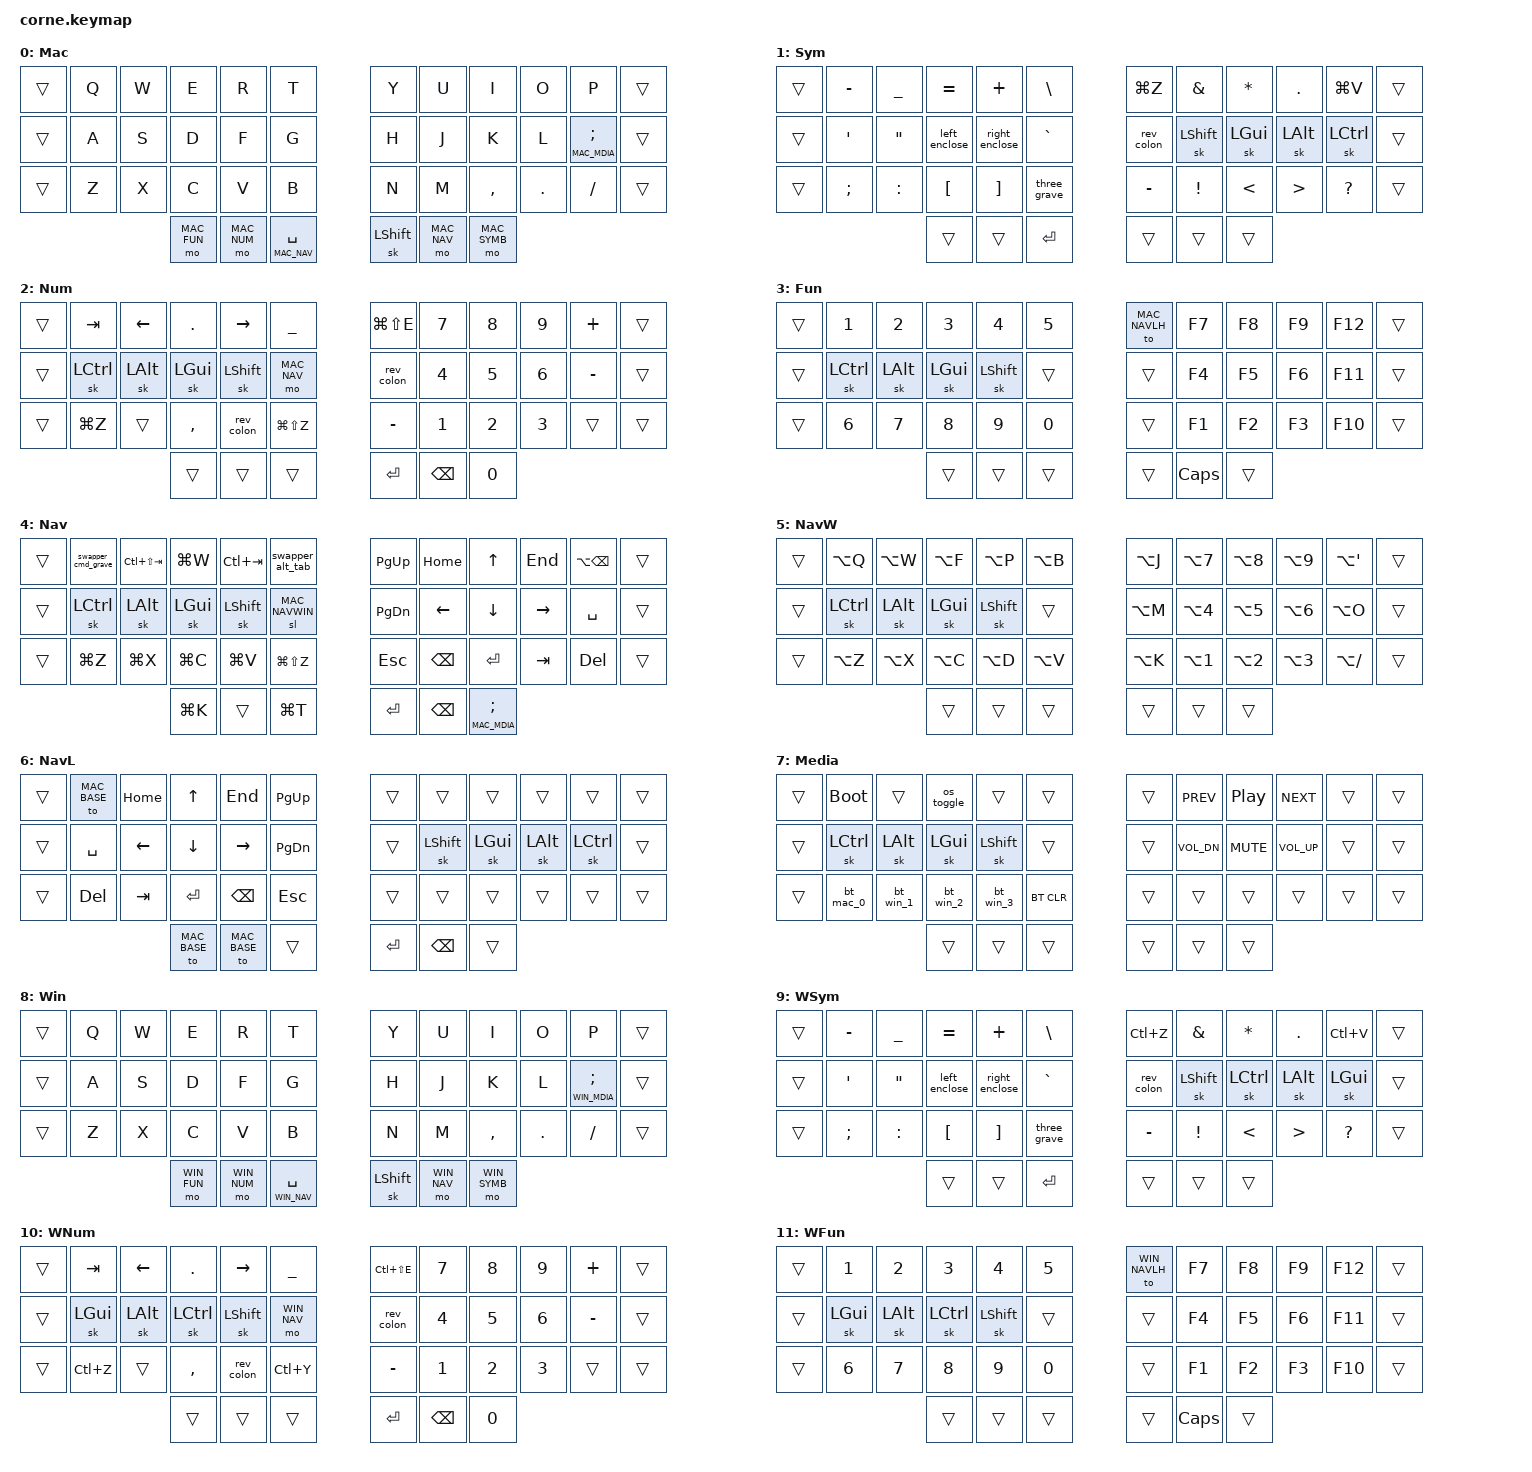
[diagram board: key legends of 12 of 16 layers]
/*
 * Copyright (c) 2020 The ZMK Contributors
 *
 * SPDX-License-Identifier: MIT
 */

#include <behaviors.dtsi>
#include <dt-bindings/zmk/keys.h>
#include <dt-bindings/zmk/bt.h>
#include <dt-bindings/zmk/outputs.h>

/* Layer definitions - Mac Mode (0-7) and Windows Mode (8-15) */
#define MAC_BASE    0
#define MAC_SYMB    1
#define MAC_NUM     2
#define MAC_FUN     3
#define MAC_NAV     4
#define MAC_NAVWIN  5
#define MAC_NAVLH   6
#define MAC_MDIA    7

#define WIN_BASE    8
#define WIN_SYMB    9
#define WIN_NUM     10
#define WIN_FUN     11
#define WIN_NAV     12
#define WIN_NAVWIN  13
#define WIN_NAVLH   14
#define WIN_MDIA    15

/* Common Key Aliases (OS-independent) */
#define BLANK              &trans

/* Letter Keys */
#define KEY_Q              &kp Q
#define KEY_W              &kp W
#define KEY_E              &kp E
#define KEY_R              &kp R
#define KEY_T              &kp T
#define KEY_Y              &kp Y
#define KEY_U              &kp U
#define KEY_I              &kp I
#define KEY_O              &kp O
#define KEY_P              &kp P
#define KEY_A              &kp A
#define KEY_S              &kp S
#define KEY_D              &kp D
#define KEY_F              &kp F
#define KEY_G              &kp G
#define KEY_H              &kp H
#define KEY_J              &kp J
#define KEY_K              &kp K
#define KEY_L              &kp L
#define KEY_Z              &kp Z
#define KEY_X              &kp X
#define KEY_C              &kp C
#define KEY_V              &kp V
#define KEY_B              &kp B
#define KEY_N              &kp N
#define KEY_M              &kp M
#define KEY_COMMA          &kp COMMA
#define KEY_DOT            &kp DOT
#define KEY_FSLH           &kp FSLH

/* Number Keys */
#define KEY_1              &kp N1
#define KEY_2              &kp N2
#define KEY_3              &kp N3
#define KEY_4              &kp N4
#define KEY_5              &kp N5
#define KEY_6              &kp N6
#define KEY_7              &kp N7
#define KEY_8              &kp N8
#define KEY_9              &kp N9
#define KEY_0              &kp N0

/* Symbol Keys */
#define SYM_MINUS          &kp MINUS
#define SYM_UNDER          &kp UNDER
#define SYM_EQUAL          &kp EQUAL
#define SYM_PLUS           &kp PLUS
#define SYM_BSLH           &kp BSLH
#define SYM_SQT            &kp SQT
#define SYM_DQT            &kp DQT
#define SYM_GRAVE          &kp GRAVE
#define SYM_SEMI           &kp SEMI
#define SYM_COLON          &kp COLON
#define SYM_LBKT           &kp LBKT
#define SYM_RBKT           &kp RBKT
#define SYM_AMPS           &kp AMPS
#define SYM_ASTRK          &kp ASTRK
#define SYM_EXCL           &kp EXCL
#define SYM_LT             &kp LT
#define SYM_GT             &kp GT
#define SYM_QMARK          &kp QMARK

/* Function Keys */
#define FUN_F1             &kp F1
#define FUN_F2             &kp F2
#define FUN_F3             &kp F3
#define FUN_F4             &kp F4
#define FUN_F5             &kp F5
#define FUN_F6             &kp F6
#define FUN_F7             &kp F7
#define FUN_F8             &kp F8
#define FUN_F9             &kp F9
#define FUN_F10            &kp F10
#define FUN_F11            &kp F11
#define FUN_F12            &kp F12

/* Navigation Keys */
#define NAV_UP             &kp UP
#define NAV_DOWN           &kp DOWN
#define NAV_LEFT           &kp LEFT
#define NAV_RIGHT          &kp RIGHT
#define NAV_HOME           &kp HOME
#define NAV_END            &kp END
#define NAV_PGUP           &kp PG_UP
#define NAV_PGDN           &kp PG_DN

/* Common Keys */
#define KEY_TAB            &kp TAB
#define KEY_RET            &kp RET
#define KEY_ESC            &kp ESC
#define KEY_BSPC           &kp BSPC
#define KEY_DEL            &kp DEL
#define KEY_SPACE          &kp SPACE
#define KEY_CAPS           &kp CAPSLOCK

/* Media Keys */
#define MED_PREV           &kp C_PREV
#define MED_NEXT           &kp C_NEXT
#define MED_PLAY           &kp C_PP
#define MED_VOL_UP         &kp C_VOL_UP
#define MED_VOL_DN         &kp C_VOL_DN
#define MED_MUTE           &kp C_MUTE

/* System Keys */
#define SYS_BOOT           &bootloader

/* Bluetooth Keys */
#define BT_MAC_0           &bt_mac_0
#define BT_WIN_1           &bt_win_1
#define BT_WIN_2           &bt_win_2
#define BT_WIN_3           &bt_win_3
#define BT_CLEAR           &bt BT_CLR

/* Alt Layer Keys */
#define ALT_Q              &kp LA(Q)
#define ALT_W              &kp LA(W)
#define ALT_F              &kp LA(F)
#define ALT_P              &kp LA(P)
#define ALT_B              &kp LA(B)
#define ALT_J              &kp LA(J)
#define ALT_M              &kp LA(M)
#define ALT_K              &kp LA(K)
#define ALT_Z              &kp LA(Z)
#define ALT_X              &kp LA(X)
#define ALT_C              &kp LA(C)
#define ALT_D              &kp LA(D)
#define ALT_V              &kp LA(V)
#define ALT_O              &kp LA(O)
#define ALT_SQT            &kp LA(SQT)
#define ALT_FSLH           &kp LA(FSLH)
#define ALT_N1             &kp LA(N1)
#define ALT_N2             &kp LA(N2)
#define ALT_N3             &kp LA(N3)
#define ALT_N4             &kp LA(N4)
#define ALT_N5             &kp LA(N5)
#define ALT_N6             &kp LA(N6)
#define ALT_N7             &kp LA(N7)
#define ALT_N8             &kp LA(N8)
#define ALT_N9             &kp LA(N9)

/* OS-Specific Modifier Keys - Mac Mode */
#define MAC_OS_SHFT        &sk LSHFT
#define MAC_OS_CTRL        &sk LCTRL
#define MAC_OS_ALT         &sk LALT
#define MAC_OS_GUI         &sk LGUI

/* OS-Specific Modifier Keys - Windows Mode (GUI and CTRL swapped) */
#define WIN_OS_SHFT        &sk LSHFT
#define WIN_OS_CTRL        &sk LGUI  // Windows "Ctrl" is GUI key
#define WIN_OS_ALT         &sk LALT
#define WIN_OS_GUI         &sk LCTRL  // Windows "GUI" is Ctrl key

/* OS-Specific Layer Access Keys */
#define MAC_FUN_KEY        &mo MAC_FUN
#define MAC_NUM_KEY        &mo MAC_NUM
#define MAC_NAV_KEY        &mo MAC_NAV
#define MAC_SYMB_KEY       &mo MAC_SYMB
#define MAC_NAVWIN_KEY     &sl MAC_NAVWIN
#define MAC_NAVLH_KEY      &to MAC_NAVLH
#define MAC_BASE_KEY       &to MAC_BASE
#define MAC_SEMI_MDIA      &lt MAC_MDIA SEMI

#define WIN_FUN_KEY        &mo WIN_FUN
#define WIN_NUM_KEY        &mo WIN_NUM
#define WIN_NAV_KEY        &mo WIN_NAV
#define WIN_SYMB_KEY       &mo WIN_SYMB
#define WIN_NAVWIN_KEY     &sl WIN_NAVWIN
#define WIN_NAVLH_KEY      &to WIN_NAVLH
#define WIN_BASE_KEY       &to WIN_BASE
#define WIN_SEMI_MDIA      &lt WIN_MDIA SEMI

/* OS-Specific Space Keys with Layer Tap */
#define MAC_SPACE          &lt_sp_mac MAC_NAV SPACE
#define WIN_SPACE          &lt_sp_win WIN_NAV SPACE

/* OS-Specific Shortcuts - Mac */
#define MAC_UNDO           &kp LG(Z)
#define MAC_CUT            &kp LG(X)
#define MAC_COPY           &kp LG(C)
#define MAC_PASTE          &kp LG(V)
#define MAC_REDO           &kp LG(LS(Z))
#define MAC_CLS_WIN        &kp LG(W)
#define MAC_NWTB           &kp LG(T)
#define MAC_MKLNK          &kp LG(K)
#define MAC_VSC_EVAL       &kp LG(LS(E))
#define MAC_DWRD           &kp LA(BSPC)

/* OS-Specific Shortcuts - Windows/Linux */
#define WIN_UNDO           &kp LC(Z)
#define WIN_CUT            &kp LC(X)
#define WIN_COPY           &kp LC(C)
#define WIN_PASTE          &kp LC(V)
#define WIN_REDO           &kp LC(Y)
#define WIN_CLS_WIN        &kp LC(W)
#define WIN_NWTB           &kp LC(T)
#define WIN_MKLNK          &kp LC(K)
#define WIN_VSC_EVAL       &kp LC(LS(E))
#define WIN_DWRD           &kp LC(BSPC)

/* Tab Navigation */
#define TAB_PREV           &kp LC(LS(TAB))
#define TAB_NEXT           &kp LC(TAB)

/* Custom Behaviors */
#define OS_TOGGLE          &os_toggle
#define REV_COLON          &rev_colon
#define LEFT_ENCLOSE       &left_enclose
#define RIGHT_ENCLOSE      &right_enclose
#define THREE_GRAVE        &three_grave
#define SW_APP             &swapper_alt_tab
#define SW_WIN             &swapper_cmd_grave

/* Custom behaviors */
/ {
    behaviors {
        // OS toggle: Switch between Mac (layers 0-7) and Windows (layers 8-15) mode
        os_toggle: os_toggle {
            compatible = "zmk,behavior-mod-morph";
            #binding-cells = <0>;
            bindings = <&to WIN_BASE>, <&to MAC_BASE>;
            mods = <(MOD_LSFT|MOD_RSFT)>;
        };

        // Swapper behavior for Alt+Tab functionality
        swapper_alt_tab: swapper_alt_tab {
            compatible = "zmk,behavior-tri-state";
            #binding-cells = <0>;
            bindings = <&kt LALT>, <&kp TAB>, <&kt LALT>;
            timeout-ms = <3000>;
        };

        // Swapper behavior for Cmd+` functionality  
        swapper_cmd_grave: swapper_cmd_grave {
            compatible = "zmk,behavior-tri-state";
            #binding-cells = <0>;
            bindings = <&kt LGUI>, <&kp GRAVE>, <&kt LGUI>;
            timeout-ms = <3000>;
        };

        // Reversed colon/semicolon (colon by default, semicolon with shift)
        rev_colon: reversed_colon {
            compatible = "zmk,behavior-mod-morph";
            #binding-cells = <0>;
            bindings = <&kp COLON>, <&kp SEMI>;
            mods = <(MOD_LSFT|MOD_RSFT)>;
        };

        // Left enclosure behavior (parenthesis by default, brace with shift)
        left_enclose: left_enclosure {
            compatible = "zmk,behavior-mod-morph";
            #binding-cells = <0>;
            bindings = <&kp LPAR>, <&kp LBRC>;
            mods = <(MOD_LSFT|MOD_RSFT)>;
        };

        // Right enclosure behavior (parenthesis by default, brace with shift)
        right_enclose: right_enclosure {
            compatible = "zmk,behavior-mod-morph";
            #binding-cells = <0>;
            bindings = <&kp RPAR>, <&kp RBRC>;
            mods = <(MOD_LSFT|MOD_RSFT)>;
        };

        // Three backticks macro
        three_grave: three_grave_macro {
            compatible = "zmk,behavior-macro";
            #binding-cells = <0>;
            bindings = <&macro_tap &kp GRAVE &kp GRAVE &kp GRAVE>;
        };

        // Custom mod-tap with longer tapping term for space - Mac version
        lt_sp_mac: layer_tap_space_mac {
            compatible = "zmk,behavior-hold-tap";
            #binding-cells = <2>;
            flavor = "balanced";
            tapping-term-ms = <200>;
            quick-tap-ms = <150>;
            bindings = <&mo>, <&kp>;
        };

        // Custom mod-tap with longer tapping term for space - Windows version
        lt_sp_win: layer_tap_space_win {
            compatible = "zmk,behavior-hold-tap";
            #binding-cells = <2>;
            flavor = "balanced";
            tapping-term-ms = <200>;
            quick-tap-ms = <150>;
            bindings = <&mo>, <&kp>;
        };

        // Smart Bluetooth selection macros that auto-switch OS modes
        bt_mac_0: bt_mac_profile_0 {
            compatible = "zmk,behavior-macro";
            #binding-cells = <0>;
            bindings = <&bt BT_SEL 0>, <&to MAC_BASE>;
        };

        bt_win_1: bt_win_profile_1 {
            compatible = "zmk,behavior-macro";
            #binding-cells = <0>;
            bindings = <&bt BT_SEL 1>, <&to WIN_BASE>;
        };

        bt_win_2: bt_win_profile_2 {
            compatible = "zmk,behavior-macro";
            #binding-cells = <0>;
            bindings = <&bt BT_SEL 2>, <&to WIN_BASE>;
        };

        bt_win_3: bt_win_profile_3 {
            compatible = "zmk,behavior-macro";
            #binding-cells = <0>;
            bindings = <&bt BT_SEL 3>, <&to WIN_BASE>;
        };
    };

    combos {
        compatible = "zmk,combos";

        // Mac mode combos
        combo_nei_ctrl_mac {
            timeout-ms = <50>;
            key-positions = <16 17 18>; // N E I positions (3x6 layout with offset)
            bindings = <&sk LCTRL>;
            layers = <MAC_BASE MAC_SYMB MAC_NUM MAC_FUN MAC_NAV MAC_NAVWIN MAC_NAVLH>;
        };

        combo_commadot_semicolon_mac {
            timeout-ms = <50>;
            key-positions = <33 34>; // Comma and Dot positions (3x6 layout with offset)
            bindings = <&kp SEMI>;
            layers = <MAC_BASE MAC_SYMB MAC_NUM MAC_FUN MAC_NAV MAC_NAVWIN MAC_NAVLH>;
        };

        combo_hcomma_hyphen_mac {
            timeout-ms = <50>;
            key-positions = <16 33>; // H and Comma positions (3x6 layout with offset)
            bindings = <&kp MINUS>;
            layers = <MAC_BASE MAC_SYMB MAC_NUM MAC_FUN MAC_NAV MAC_NAVWIN MAC_NAVLH>;
        };

        combo_zd_tab_mac {
            timeout-ms = <50>;
            key-positions = <25 15>; // Z and D positions (3x6 layout with offset)
            bindings = <&kp TAB>;
            layers = <MAC_BASE MAC_SYMB MAC_NUM MAC_FUN MAC_NAV MAC_NAVWIN MAC_NAVLH>;
        };

        combo_xd_ctrl_mac {
            timeout-ms = <50>;
            key-positions = <26 15>; // X and D positions (3x6 layout with offset)
            bindings = <&sk LCTRL>;
            layers = <MAC_BASE MAC_SYMB MAC_NUM MAC_FUN MAC_NAV MAC_NAVWIN MAC_NAVLH>;
        };

        combo_dh_ctrl_mac {
            timeout-ms = <50>;
            key-positions = <15 18>; // D and H positions (3x6 layout with offset)
            bindings = <&sk LCTRL>;
            layers = <MAC_BASE MAC_SYMB MAC_NUM MAC_FUN MAC_NAV MAC_NAVWIN MAC_NAVLH>;
        };

        combo_prev_next_select_all_mac {
            timeout-ms = <50>;
            key-positions = <4 5>; // R and T positions (3x6 layout with offset)
            bindings = <&kp LG(A)>;
            layers = <MAC_BASE MAC_SYMB MAC_NUM MAC_FUN MAC_NAV MAC_NAVWIN MAC_NAVLH>;
        };

        // Windows mode combos (identical positions, different bindings)
        combo_nei_ctrl_win {
            timeout-ms = <50>;
            key-positions = <16 17 18>; // N E I positions (3x6 layout with offset)
            bindings = <&sk LGUI>;
            layers = <WIN_BASE WIN_SYMB WIN_NUM WIN_FUN WIN_NAV WIN_NAVWIN WIN_NAVLH>;
        };

        combo_commadot_semicolon_win {
            timeout-ms = <50>;
            key-positions = <33 34>; // Comma and Dot positions (3x6 layout with offset)
            bindings = <&kp SEMI>;
            layers = <WIN_BASE WIN_SYMB WIN_NUM WIN_FUN WIN_NAV WIN_NAVWIN WIN_NAVLH>;
        };

        combo_hcomma_hyphen_win {
            timeout-ms = <50>;
            key-positions = <16 33>; // H and Comma positions (3x6 layout with offset)
            bindings = <&kp MINUS>;
            layers = <WIN_BASE WIN_SYMB WIN_NUM WIN_FUN WIN_NAV WIN_NAVWIN WIN_NAVLH>;
        };

        combo_zd_tab_win {
            timeout-ms = <50>;
            key-positions = <25 15>; // Z and D positions (3x6 layout with offset)
            bindings = <&kp TAB>;
            layers = <WIN_BASE WIN_SYMB WIN_NUM WIN_FUN WIN_NAV WIN_NAVWIN WIN_NAVLH>;
        };

        combo_xd_ctrl_win {
            timeout-ms = <50>;
            key-positions = <26 15>; // X and D positions (3x6 layout with offset)
            bindings = <&sk LGUI>;
            layers = <WIN_BASE WIN_SYMB WIN_NUM WIN_FUN WIN_NAV WIN_NAVWIN WIN_NAVLH>;
        };

        combo_dh_ctrl_win {
            timeout-ms = <50>;
            key-positions = <15 18>; // D and H positions (3x6 layout with offset)
            bindings = <&sk LGUI>;
            layers = <WIN_BASE WIN_SYMB WIN_NUM WIN_FUN WIN_NAV WIN_NAVWIN WIN_NAVLH>;
        };

        combo_prev_next_select_all_win {
            timeout-ms = <50>;
            key-positions = <4 5>; // R and T positions (3x6 layout with offset)
            bindings = <&kp LC(A)>;
            layers = <WIN_BASE WIN_SYMB WIN_NUM WIN_FUN WIN_NAV WIN_NAVWIN WIN_NAVLH>;
        };
    };

        keymap {
                compatible = "zmk,keymap";

        // MAC MODE LAYERS (0-7)
        mac_base_layer {
            display-name = "Mac";
            bindings = <
            // ╭─────────┬─────────┬─────────┬─────────┬─────────╮   ╭─────────┬─────────┬─────────┬─────────┬─────────╮
        BLANK     KEY_Q     KEY_W     KEY_E     KEY_R     KEY_T         KEY_Y     KEY_U     KEY_I     KEY_O     KEY_P        BLANK
            // ├─────────┼─────────┼─────────┼─────────┼─────────┤   ├─────────┼─────────┼─────────┼─────────┼─────────┤
        BLANK     KEY_A     KEY_S     KEY_D     KEY_F     KEY_G         KEY_H     KEY_J     KEY_K     KEY_L   MAC_SEMI_MDIA  BLANK
            // ├─────────┼─────────┼─────────┼─────────┼─────────┤   ├─────────┼─────────┼─────────┼─────────┼─────────┤
        BLANK     KEY_Z     KEY_X     KEY_C     KEY_V     KEY_B         KEY_N     KEY_M   KEY_COMMA  KEY_DOT   KEY_FSLH      BLANK
            // ╰─────────┴─────────┼─────────┼─────────┼─────────┤   ├─────────┼─────────┼─────────┴─────────┴─────────╯
                                   MAC_FUN_KEY MAC_NUM_KEY MAC_SPACE MAC_OS_SHFT MAC_NAV_KEY MAC_SYMB_KEY
            //                     ╰─────────┴─────────┴─────────╯   ╰─────────┴─────────┴─────────╯
            >;
        };

        mac_symb_layer {
            display-name = "Sym";
            bindings = <
            // ╭─────────┬─────────┬─────────┬─────────┬─────────╮   ╭─────────┬─────────┬─────────┬─────────┬─────────╮
        BLANK   SYM_MINUS SYM_UNDER SYM_EQUAL  SYM_PLUS  SYM_BSLH    MAC_UNDO  SYM_AMPS  SYM_ASTRK  KEY_DOT  MAC_PASTE   BLANK
            // ├─────────┼─────────┼─────────┼─────────┼─────────┤   ├─────────┼─────────┼─────────┼─────────┼─────────┤
        BLANK    SYM_SQT   SYM_DQT  LEFT_ENCLOSE RIGHT_ENCLOSE SYM_GRAVE REV_COLON MAC_OS_SHFT MAC_OS_GUI MAC_OS_ALT MAC_OS_CTRL BLANK
            // ├─────────┼─────────┼─────────┼─────────┼─────────┤   ├─────────┼─────────┼─────────┼─────────┼─────────┤
        BLANK   SYM_SEMI  SYM_COLON  SYM_LBKT   SYM_RBKT THREE_GRAVE SYM_MINUS  SYM_EXCL   SYM_LT    SYM_GT  SYM_QMARK   BLANK
            // ╰─────────┴─────────┼─────────┼─────────┼─────────┤   ├─────────┼─────────┼─────────┴─────────┴─────────╯
                                     BLANK       BLANK      KEY_RET     BLANK       BLANK       BLANK
            //                     ╰─────────┴─────────┴─────────╯   ╰─────────┴─────────┴─────────╯
            >;
        };

        mac_num_layer {
            display-name = "Num";
            bindings = <
            // ╭─────────┬─────────┬─────────┬─────────┬─────────╮   ╭─────────┬─────────┬─────────┬─────────┬─────────╮
        BLANK    KEY_TAB   NAV_LEFT   KEY_DOT  NAV_RIGHT SYM_UNDER MAC_VSC_EVAL  KEY_7     KEY_8     KEY_9    SYM_PLUS    BLANK
            // ├─────────┼─────────┼─────────┼─────────┼─────────┤   ├─────────┼─────────┼─────────┼─────────┼─────────┤
        BLANK  MAC_OS_CTRL MAC_OS_ALT MAC_OS_GUI MAC_OS_SHFT MAC_NAV_KEY REV_COLON  KEY_4     KEY_5     KEY_6   SYM_MINUS   BLANK
            // ├─────────┼─────────┼─────────┼─────────┼─────────┤   ├─────────┼─────────┼─────────┼─────────┼─────────┤
        BLANK   MAC_UNDO    BLANK    KEY_COMMA REV_COLON MAC_REDO  SYM_MINUS   KEY_1     KEY_2     KEY_3      BLANK      BLANK
            // ╰─────────┴─────────┼─────────┼─────────┼─────────┤   ├─────────┼─────────┼─────────┴─────────┴─────────╯
                                     BLANK       BLANK      BLANK     KEY_RET   KEY_BSPC    KEY_0
            //                     ╰─────────┴─────────┴─────────╯   ╰─────────┴─────────┴─────────╯
            >;
        };

        mac_fun_layer {
            display-name = "Fun";
            bindings = <
            // ╭─────────┬─────────┬─────────┬─────────┬─────────╮   ╭─────────┬─────────┬─────────┬─────────┬─────────╮
        BLANK     KEY_1     KEY_2     KEY_3     KEY_4     KEY_5   MAC_NAVLH_KEY FUN_F7    FUN_F8    FUN_F9   FUN_F12     BLANK
            // ├─────────┼─────────┼─────────┼─────────┼─────────┤   ├─────────┼─────────┼─────────┼─────────┼─────────┤
        BLANK  MAC_OS_CTRL MAC_OS_ALT MAC_OS_GUI MAC_OS_SHFT  BLANK      BLANK     FUN_F4    FUN_F5    FUN_F6   FUN_F11     BLANK
            // ├─────────┼─────────┼─────────┼─────────┼─────────┤   ├─────────┼─────────┼─────────┼─────────┼─────────┤
        BLANK     KEY_6     KEY_7     KEY_8     KEY_9     KEY_0      BLANK     FUN_F1    FUN_F2    FUN_F3   FUN_F10     BLANK
            // ╰─────────┴─────────┼─────────┼─────────┼─────────┤   ├─────────┼─────────┼─────────┴─────────┴─────────╯
                                     BLANK       BLANK      BLANK      BLANK    KEY_CAPS    BLANK
            //                     ╰─────────┴─────────┴─────────╯   ╰─────────┴─────────┴─────────╯
            >;
        };

        mac_nav_layer {
            display-name = "Nav";
            bindings = <
            // ╭─────────┬─────────┬─────────┬─────────┬─────────╮   ╭─────────┬─────────┬─────────┬─────────┬─────────╮
        BLANK    SW_WIN   TAB_PREV MAC_CLS_WIN TAB_NEXT   SW_APP    NAV_PGUP  NAV_HOME   NAV_UP    NAV_END  MAC_DWRD    BLANK
            // ├─────────┼─────────┼─────────┼─────────┼─────────┤   ├─────────┼─────────┼─────────┼─────────┼─────────┤
        BLANK  MAC_OS_CTRL MAC_OS_ALT MAC_OS_GUI MAC_OS_SHFT MAC_NAVWIN_KEY NAV_PGDN NAV_LEFT  NAV_DOWN NAV_RIGHT KEY_SPACE  BLANK
            // ├─────────┼─────────┼─────────┼─────────┼─────────┤   ├─────────┼─────────┼─────────┼─────────┼─────────┤
        BLANK   MAC_UNDO  MAC_CUT   MAC_COPY  MAC_PASTE MAC_REDO   KEY_ESC   KEY_BSPC  KEY_RET   KEY_TAB   KEY_DEL    BLANK
            // ╰─────────┴─────────┼─────────┼─────────┼─────────┤   ├─────────┼─────────┼─────────┴─────────┴─────────╯
                                   MAC_MKLNK    BLANK    MAC_NWTB   KEY_RET   KEY_BSPC MAC_SEMI_MDIA
            //                     ╰─────────┴─────────┴─────────╯   ╰─────────┴─────────┴─────────╯
            >;
        };

        mac_navwin_layer {
            display-name = "NavW";
            bindings = <
            // ╭─────────┬─────────┬─────────┬─────────┬─────────╮   ╭─────────┬─────────┬─────────┬─────────┬─────────╮
        BLANK     ALT_Q     ALT_W     ALT_F     ALT_P     ALT_B      ALT_J     ALT_N7    ALT_N8    ALT_N9    ALT_SQT    BLANK
            // ├─────────┼─────────┼─────────┼─────────┼─────────┤   ├─────────┼─────────┼─────────┼─────────┼─────────┤
        BLANK  MAC_OS_CTRL MAC_OS_ALT MAC_OS_GUI MAC_OS_SHFT  BLANK     ALT_M     ALT_N4    ALT_N5    ALT_N6     ALT_O     BLANK
            // ├─────────┼─────────┼─────────┼─────────┼─────────┤   ├─────────┼─────────┼─────────┼─────────┼─────────┤
        BLANK     ALT_Z     ALT_X     ALT_C     ALT_D     ALT_V      ALT_K     ALT_N1    ALT_N2    ALT_N3   ALT_FSLH    BLANK
            // ╰─────────┴─────────┼─────────┼─────────┼─────────┤   ├─────────┼─────────┼─────────┴─────────┴─────────╯
                                     BLANK       BLANK      BLANK      BLANK       BLANK       BLANK
            //                     ╰─────────┴─────────┴─────────╯   ╰─────────┴─────────┴─────────╯
            >;
        };

        mac_navlh_layer {
            display-name = "NavL";
            bindings = <
            // ╭─────────┬─────────┬─────────┬─────────┬─────────╮   ╭─────────┬─────────┬─────────┬─────────┬─────────╮
        BLANK  MAC_BASE_KEY NAV_HOME   NAV_UP    NAV_END  NAV_PGUP     BLANK     BLANK     BLANK     BLANK     BLANK      BLANK
            // ├─────────┼─────────┼─────────┼─────────┼─────────┤   ├─────────┼─────────┼─────────┼─────────┼─────────┤
        BLANK   KEY_SPACE  NAV_LEFT  NAV_DOWN NAV_RIGHT NAV_PGDN     BLANK   MAC_OS_SHFT MAC_OS_GUI MAC_OS_ALT MAC_OS_CTRL BLANK
            // ├─────────┼─────────┼─────────┼─────────┼─────────┤   ├─────────┼─────────┼─────────┼─────────┼─────────┤
        BLANK    KEY_DEL   KEY_TAB   KEY_RET   KEY_BSPC  KEY_ESC      BLANK     BLANK     BLANK     BLANK     BLANK      BLANK
            // ╰─────────┴─────────┼─────────┼─────────┼─────────┤   ├─────────┼─────────┼─────────┴─────────┴─────────╯
                                 MAC_BASE_KEY MAC_BASE_KEY BLANK     KEY_RET   KEY_BSPC    BLANK
            //                     ╰─────────┴─────────┴─────────╯   ╰─────────┴─────────┴─────────╯
            >;
        };

        // MAC MEDIA LAYER (7)
        mac_mdia_layer {
            display-name = "Media";
            bindings = <
            // ╭─────────┬─────────┬─────────┬─────────┬─────────╮   ╭─────────┬─────────┬─────────┬─────────┬─────────╮
        BLANK   SYS_BOOT    BLANK   OS_TOGGLE   BLANK     BLANK         BLANK    MED_PREV MED_PLAY  MED_NEXT    BLANK      BLANK
            // ├─────────┼─────────┼─────────┼─────────┼─────────┤   ├─────────┼─────────┼─────────┼─────────┼─────────┤
        BLANK  MAC_OS_CTRL MAC_OS_ALT MAC_OS_GUI MAC_OS_SHFT  BLANK     BLANK   MED_VOL_DN MED_MUTE  MED_VOL_UP    BLANK      BLANK
            // ├─────────┼─────────┼─────────┼─────────┼─────────┤   ├─────────┼─────────┼─────────┼─────────┼─────────┤
        BLANK   BT_MAC_0   BT_WIN_1   BT_WIN_2   BT_WIN_3   BT_CLEAR    BLANK     BLANK     BLANK     BLANK     BLANK      BLANK
            // ╰─────────┴─────────┼─────────┼─────────┼─────────┤   ├─────────┼─────────┼─────────┴─────────┴─────────╯
                                     BLANK       BLANK      BLANK      BLANK       BLANK       BLANK
            //                     ╰─────────┴─────────┴─────────╯   ╰─────────┴─────────┴─────────╯
            >;
        };

        // WINDOWS MODE LAYERS (8-15)
        win_base_layer {
            display-name = "Win";
            bindings = <
            // ╭─────────┬─────────┬─────────┬─────────┬─────────╮   ╭─────────┬─────────┬─────────┬─────────┬─────────╮
        BLANK     KEY_Q     KEY_W     KEY_E     KEY_R     KEY_T         KEY_Y     KEY_U     KEY_I     KEY_O     KEY_P        BLANK
            // ├─────────┼─────────┼─────────┼─────────┼─────────┤   ├─────────┼─────────┼─────────┼─────────┼─────────┤
        BLANK     KEY_A     KEY_S     KEY_D     KEY_F     KEY_G         KEY_H     KEY_J     KEY_K     KEY_L   WIN_SEMI_MDIA  BLANK
            // ├─────────┼─────────┼─────────┼─────────┼─────────┤   ├─────────┼─────────┼─────────┼─────────┼─────────┤
        BLANK     KEY_Z     KEY_X     KEY_C     KEY_V     KEY_B         KEY_N     KEY_M   KEY_COMMA  KEY_DOT   KEY_FSLH      BLANK
            // ╰─────────┴─────────┼─────────┼─────────┼─────────┤   ├─────────┼─────────┼─────────┴─────────┴─────────╯
                                    WIN_FUN_KEY WIN_NUM_KEY WIN_SPACE WIN_OS_SHFT WIN_NAV_KEY WIN_SYMB_KEY
            //                     ╰─────────┴─────────┴─────────╯   ╰─────────┴─────────┴─────────╯
            >;
        };

        win_symb_layer {
            display-name = "WSym";
            bindings = <
            // ╭─────────┬─────────┬─────────┬─────────┬─────────╮   ╭─────────┬─────────┬─────────┬─────────┬─────────╮
        BLANK   SYM_MINUS SYM_UNDER SYM_EQUAL  SYM_PLUS  SYM_BSLH    WIN_UNDO  SYM_AMPS  SYM_ASTRK  KEY_DOT  WIN_PASTE   BLANK
            // ├─────────┼─────────┼─────────┼─────────┼─────────┤   ├─────────┼─────────┼─────────┼─────────┼─────────┤
        BLANK    SYM_SQT   SYM_DQT  LEFT_ENCLOSE RIGHT_ENCLOSE SYM_GRAVE REV_COLON WIN_OS_SHFT WIN_OS_GUI WIN_OS_ALT WIN_OS_CTRL BLANK
            // ├─────────┼─────────┼─────────┼─────────┼─────────┤   ├─────────┼─────────┼─────────┼─────────┼─────────┤
        BLANK   SYM_SEMI  SYM_COLON  SYM_LBKT   SYM_RBKT THREE_GRAVE SYM_MINUS  SYM_EXCL   SYM_LT    SYM_GT  SYM_QMARK   BLANK
            // ╰─────────┴─────────┼─────────┼─────────┼─────────┤   ├─────────┼─────────┼─────────┴─────────┴─────────╯
                                     BLANK       BLANK      KEY_RET     BLANK       BLANK       BLANK
            //                     ╰─────────┴─────────┴─────────╯   ╰─────────┴─────────┴─────────╯
            >;
        };

        win_num_layer {
            display-name = "WNum";
            bindings = <
            // ╭─────────┬─────────┬─────────┬─────────┬─────────╮   ╭─────────┬─────────┬─────────┬─────────┬─────────╮
        BLANK    KEY_TAB   NAV_LEFT   KEY_DOT  NAV_RIGHT SYM_UNDER WIN_VSC_EVAL  KEY_7     KEY_8     KEY_9    SYM_PLUS    BLANK
            // ├─────────┼─────────┼─────────┼─────────┼─────────┤   ├─────────┼─────────┼─────────┼─────────┼─────────┤
        BLANK  WIN_OS_CTRL WIN_OS_ALT WIN_OS_GUI WIN_OS_SHFT WIN_NAV_KEY REV_COLON  KEY_4     KEY_5     KEY_6   SYM_MINUS   BLANK
            // ├─────────┼─────────┼─────────┼─────────┼─────────┤   ├─────────┼─────────┼─────────┼─────────┼─────────┤
        BLANK   WIN_UNDO    BLANK    KEY_COMMA REV_COLON WIN_REDO  SYM_MINUS   KEY_1     KEY_2     KEY_3      BLANK      BLANK
            // ╰─────────┴─────────┼─────────┼─────────┼─────────┤   ├─────────┼─────────┼─────────┴─────────┴─────────╯
                                     BLANK       BLANK      BLANK     KEY_RET   KEY_BSPC    KEY_0
            //                     ╰─────────┴─────────┴─────────╯   ╰─────────┴─────────┴─────────╯
            >;
        };

        win_fun_layer {
            display-name = "WFun";
            bindings = <
            // ╭─────────┬─────────┬─────────┬─────────┬─────────╮   ╭─────────┬─────────┬─────────┬─────────┬─────────╮
        BLANK     KEY_1     KEY_2     KEY_3     KEY_4     KEY_5   WIN_NAVLH_KEY FUN_F7    FUN_F8    FUN_F9   FUN_F12     BLANK
            // ├─────────┼─────────┼─────────┼─────────┼─────────┤   ├─────────┼─────────┼─────────┼─────────┼─────────┤
        BLANK  WIN_OS_CTRL WIN_OS_ALT WIN_OS_GUI WIN_OS_SHFT  BLANK      BLANK     FUN_F4    FUN_F5    FUN_F6   FUN_F11     BLANK
            // ├─────────┼─────────┼─────────┼─────────┼─────────┤   ├─────────┼─────────┼─────────┼─────────┼─────────┤
        BLANK     KEY_6     KEY_7     KEY_8     KEY_9     KEY_0      BLANK     FUN_F1    FUN_F2    FUN_F3   FUN_F10     BLANK
            // ╰─────────┴─────────┼─────────┼─────────┼─────────┤   ├─────────┼─────────┼─────────┴─────────┴─────────╯
                                     BLANK       BLANK      BLANK      BLANK    KEY_CAPS    BLANK
            //                     ╰─────────┴─────────┴─────────╯   ╰─────────┴─────────┴─────────╯
            >;
        };

        win_nav_layer {
            display-name = "WNav";
            bindings = <
            // ╭─────────┬─────────┬─────────┬─────────┬─────────╮   ╭─────────┬─────────┬─────────┬─────────┬─────────╮
        BLANK    SW_WIN   TAB_PREV WIN_CLS_WIN TAB_NEXT   SW_APP    NAV_PGUP  NAV_HOME   NAV_UP    NAV_END  WIN_DWRD    BLANK
            // ├─────────┼─────────┼─────────┼─────────┼─────────┤   ├─────────┼─────────┼─────────┼─────────┼─────────┤
        BLANK  WIN_OS_CTRL WIN_OS_ALT WIN_OS_GUI WIN_OS_SHFT WIN_NAVWIN_KEY NAV_PGDN NAV_LEFT  NAV_DOWN NAV_RIGHT KEY_SPACE  BLANK
            // ├─────────┼─────────┼─────────┼─────────┼─────────┤   ├─────────┼─────────┼─────────┼─────────┼─────────┤
        BLANK   WIN_UNDO  WIN_CUT   WIN_COPY  WIN_PASTE WIN_REDO   KEY_ESC   KEY_BSPC  KEY_RET   KEY_TAB   KEY_DEL    BLANK
            // ╰─────────┴─────────┼─────────┼─────────┼─────────┤   ├─────────┼─────────┼─────────┴─────────┴─────────╯
                                   WIN_MKLNK    BLANK    WIN_NWTB   KEY_RET   KEY_BSPC WIN_SEMI_MDIA
            //                     ╰─────────┴─────────┴─────────╯   ╰─────────┴─────────┴─────────╯
            >;
        };

        win_navwin_layer {
            display-name = "WNavW";
            bindings = <
            // ╭─────────┬─────────┬─────────┬─────────┬─────────╮   ╭─────────┬─────────┬─────────┬─────────┬─────────╮
        BLANK     ALT_Q     ALT_W     ALT_F     ALT_P     ALT_B      ALT_J     ALT_N7    ALT_N8    ALT_N9    ALT_SQT    BLANK
            // ├─────────┼─────────┼─────────┼─────────┼─────────┤   ├─────────┼─────────┼─────────┼─────────┼─────────┤
        BLANK  WIN_OS_CTRL WIN_OS_ALT WIN_OS_GUI WIN_OS_SHFT  BLANK     ALT_M     ALT_N4    ALT_N5    ALT_N6     ALT_O     BLANK
            // ├─────────┼─────────┼─────────┼─────────┼─────────┤   ├─────────┼─────────┼─────────┼─────────┼─────────┤
        BLANK     ALT_Z     ALT_X     ALT_C     ALT_D     ALT_V      ALT_K     ALT_N1    ALT_N2    ALT_N3   ALT_FSLH    BLANK
            // ╰─────────┴─────────┼─────────┼─────────┼─────────┤   ├─────────┼─────────┼─────────┴─────────┴─────────╯
                                     BLANK       BLANK      BLANK      BLANK       BLANK       BLANK
            //                     ╰─────────┴─────────┴─────────╯   ╰─────────┴─────────┴─────────╯
            >;
        };

        win_navlh_layer {
            display-name = "WNavL";
            bindings = <
            // ╭─────────┬─────────┬─────────┬─────────┬─────────╮   ╭─────────┬─────────┬─────────┬─────────┬─────────╮
        BLANK  WIN_BASE_KEY NAV_HOME   NAV_UP    NAV_END  NAV_PGUP     BLANK     BLANK     BLANK     BLANK     BLANK      BLANK
            // ├─────────┼─────────┼─────────┼─────────┼─────────┤   ├─────────┼─────────┼─────────┼─────────┼─────────┤
        BLANK   KEY_SPACE  NAV_LEFT  NAV_DOWN NAV_RIGHT NAV_PGDN     BLANK   WIN_OS_SHFT WIN_OS_GUI WIN_OS_ALT WIN_OS_CTRL BLANK
            // ├─────────┼─────────┼─────────┼─────────┼─────────┤   ├─────────┼─────────┼─────────┼─────────┼─────────┤
        BLANK    KEY_DEL   KEY_TAB   KEY_RET   KEY_BSPC  KEY_ESC      BLANK     BLANK     BLANK     BLANK     BLANK      BLANK
            // ╰─────────┴─────────┼─────────┼─────────┼─────────┤   ├─────────┼─────────┼─────────┴─────────┴─────────╯
                                 WIN_BASE_KEY WIN_BASE_KEY BLANK     KEY_RET   KEY_BSPC    BLANK
            //                     ╰─────────┴─────────┴─────────╯   ╰─────────┴─────────┴─────────╯
            >;
        };

        // WINDOWS MEDIA LAYER (15)
        win_mdia_layer {
            display-name = "WMedia";
            bindings = <
            // ╭─────────┬─────────┬─────────┬─────────┬─────────╮   ╭─────────┬─────────┬─────────┬─────────┬─────────╮
        BLANK   SYS_BOOT    BLANK   OS_TOGGLE   BLANK     BLANK      BLANK    MED_PREV   MED_PLAY MED_NEXT    BLANK      BLANK
            // ├─────────┼─────────┼─────────┼─────────┼─────────┤   ├─────────┼─────────┼─────────┼─────────┼─────────┤
        BLANK  WIN_OS_CTRL WIN_OS_ALT WIN_OS_GUI WIN_OS_SHFT  BLANK     BLANK   MED_VOL_DN MED_MUTE  MED_VOL_UP    BLANK      BLANK
            // ├─────────┼─────────┼─────────┼─────────┼─────────┤   ├─────────┼─────────┼─────────┼─────────┼─────────┤
        BLANK   BT_MAC_0   BT_WIN_1   BT_WIN_2   BT_WIN_3   BT_CLEAR    BLANK     BLANK     BLANK     BLANK     BLANK      BLANK
            // ╰─────────┴─────────┼─────────┼─────────┼─────────┤   ├─────────┼─────────┼─────────┴─────────┴─────────╯
                                     BLANK       BLANK      BLANK      BLANK       BLANK       BLANK
            //                     ╰─────────┴─────────┴─────────╯   ╰─────────┴─────────┴─────────╯
            >;
        };
    };
};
